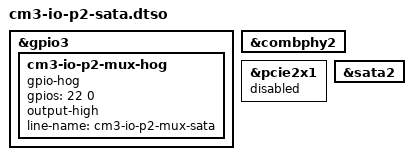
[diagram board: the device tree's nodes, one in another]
// SPDX-License-Identifier: GPL-2.0

/dts-v1/;
/plugin/;

/ {
	fragment@0 {
		target = <&gpio3>;
		__overlay__ {
			cm3-io-p2-mux-hog {
				gpio-hog;
				gpios = <22 0>;
				output-high;
				line-name = "cm3-io-p2-mux-sata";
			};
		};
	};

	fragment@1 {
		target = <&combphy2>;
		__overlay__ {
			status = "okay";
		};
	};

	fragment@2 {
		target = <&pcie2x1>;
		__overlay__ {
			status = "disabled";
		};
	};

	fragment@3 {
		target = <&sata2>;
		__overlay__ {
			status = "okay";
		};
	};
};
